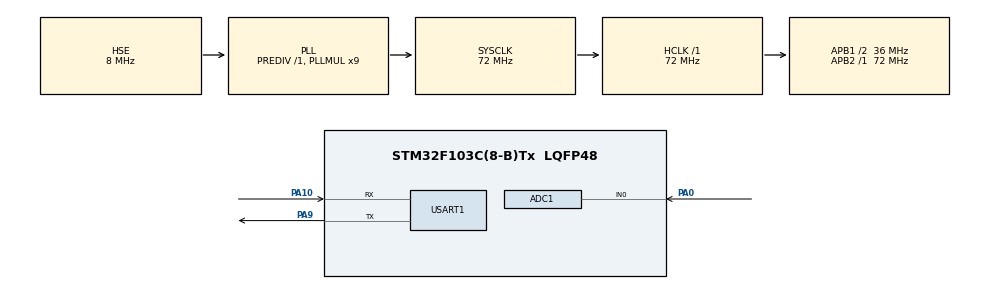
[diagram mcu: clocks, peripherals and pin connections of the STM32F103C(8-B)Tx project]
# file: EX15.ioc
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ADC1.ContinuousConvMode=ENABLE
ADC1.EnableRegularConversion=DISABLE
ADC1.master=1
FREERTOS.Queues01=Queue01,16,uint16_t,0,Dynamic,NULL,NULL
FREERTOS.Tasks01=Task01,0,128,Task01Funct,Default,NULL,Dynamic,NULL,NULL;Task02,0,128,Task02Funct,Default,NULL,Dynamic,NULL,NULL
Mcu.Family=STM32F1
Mcu.Name=STM32F103C(8-B)Tx
Mcu.Package=LQFP48
NVIC.PriorityGroup=NVIC_PRIORITYGROUP_4
NVIC.TIM1_UP_IRQn=true\:15\:0\:false\:false\:true\:false\:false\:true\:true
NVIC.TimeBase=TIM1_UP_IRQn
NVIC.TimeBaseIP=TIM1
PA0-WKUP.Signal=ADCx_IN0
PA10.Mode=Asynchronous
PA10.Signal=USART1_RX
PA13.Mode=Serial_Wire
PA13.Signal=SYS_JTMS-SWDIO
PA14.Mode=Serial_Wire
PA14.Signal=SYS_JTCK-SWCLK
PA9.Mode=Asynchronous
PA9.Signal=USART1_TX
PD0-OSC_IN.Mode=HSE-External-Oscillator
PD0-OSC_IN.Signal=RCC_OSC_IN
PD1-OSC_OUT.Mode=HSE-External-Oscillator
PD1-OSC_OUT.Signal=RCC_OSC_OUT
ProjectManager.HeapSize=0x200
ProjectManager.StackSize=0x400
ProjectManager.TargetToolchain=MDK-ARM V5.32
RCC.ADCPresc=RCC_ADCPCLK2_DIV6
RCC.AHBFreq_Value=72000000
RCC.APB1CLKDivider=RCC_HCLK_DIV2
RCC.APB1Freq_Value=36000000
RCC.APB1TimFreq_Value=72000000
RCC.APB2Freq_Value=72000000
RCC.APB2TimFreq_Value=72000000
RCC.HCLKFreq_Value=72000000
RCC.PLLMUL=RCC_PLL_MUL9
RCC.PLLSourceVirtual=RCC_PLLSOURCE_HSE
RCC.SYSCLKFreq_VALUE=72000000
RCC.SYSCLKSource=RCC_SYSCLKSOURCE_PLLCLK
RCC.USBFreq_Value=72000000
SH.ADCx_IN0.0=ADC1_IN0,IN0
USART1.VirtualMode=VM_ASYNC
VP_FREERTOS_VS_CMSIS_V1.Mode=CMSIS_V1
VP_SYS_VS_tim1.Mode=TIM1
board=custom

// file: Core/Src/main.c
/* USER CODE BEGIN Header */
/**
  ******************************************************************************
  * @file           : main.c
  * @brief          : Main program body
  ******************************************************************************
  * @attention
  *
  * Copyright (c) 2025 STMicroelectronics.
  * All rights reserved.
  *
  * This software is licensed under terms that can be found in the LICENSE file
  * in the root directory of this software component.
  * If no LICENSE file comes with this software, it is provided AS-IS.
  *
  ******************************************************************************
  */
/* USER CODE END Header */
#include "main.h"
#include "cmsis_os.h"

/* USER CODE BEGIN Includes */
#include "string.h"
#include "stdio.h"
/* USER CODE END Includes */

ADC_HandleTypeDef hadc1;

UART_HandleTypeDef huart1;

osThreadId Task01Handle;
osThreadId Task02Handle;
osMessageQId Queue01Handle;

void SystemClock_Config(void);
static void MX_GPIO_Init(void);
static void MX_ADC1_Init(void);
static void MX_USART1_UART_Init(void);
void Task01Funct(void const * argument);
void Task02Funct(void const * argument);

/* USER CODE BEGIN 0 */
void UART1_SendChar(char c){
	HAL_UART_Transmit(&huart1, (uint8_t*)&c, 1, 10);
}

struct __FILE {
    int dummy;
};
FILE __stdout;
int fputc(int ch, FILE *f){
	UART1_SendChar(ch);
	return ch;
}

uint16_t Read_ADC_Value(void){
	uint16_t value = 0;

	HAL_ADC_PollForConversion(&hadc1, 100);
	value = HAL_ADC_GetValue(&hadc1);
	return value;
}

/* USER CODE END 0 */

int main(void)
{

  /* MCU Configuration--------------------------------------------------------*/

  /* Reset of all peripherals, Initializes the Flash interface and the Systick. */
  HAL_Init();

  /* Configure the system clock */
  SystemClock_Config();

  /* Initialize all configured peripherals */
  MX_GPIO_Init();
  MX_ADC1_Init();
  MX_USART1_UART_Init();

  /* Create the queue(s) */
  /* definition and creation of Queue01 */
  osMessageQDef(Queue01, 16, uint16_t);
  Queue01Handle = osMessageCreate(osMessageQ(Queue01), NULL);

  /* Create the thread(s) */
  /* definition and creation of Task01 */
  osThreadDef(Task01, Task01Funct, osPriorityNormal, 0, 128);
  Task01Handle = osThreadCreate(osThread(Task01), NULL);

  /* definition and creation of Task02 */
  osThreadDef(Task02, Task02Funct, osPriorityNormal, 0, 128);
  Task02Handle = osThreadCreate(osThread(Task02), NULL);

  /* Start scheduler */
  osKernelStart();

  /* We should never get here as control is now taken by the scheduler */

  /* Infinite loop */
  while (1)
  {

  }
}

void SystemClock_Config(void)
{
  RCC_OscInitTypeDef RCC_OscInitStruct = {0};
  RCC_ClkInitTypeDef RCC_ClkInitStruct = {0};
  RCC_PeriphCLKInitTypeDef PeriphClkInit = {0};

  /** Initializes the RCC Oscillators according to the specified parameters
  * in the RCC_OscInitTypeDef structure.
  */
  RCC_OscInitStruct.OscillatorType = RCC_OSCILLATORTYPE_HSE;
  RCC_OscInitStruct.HSEState = RCC_HSE_ON;
  RCC_OscInitStruct.HSEPredivValue = RCC_HSE_PREDIV_DIV1;
  RCC_OscInitStruct.HSIState = RCC_HSI_ON;
  RCC_OscInitStruct.PLL.PLLState = RCC_PLL_ON;
  RCC_OscInitStruct.PLL.PLLSource = RCC_PLLSOURCE_HSE;
  RCC_OscInitStruct.PLL.PLLMUL = RCC_PLL_MUL9;
  if (HAL_RCC_OscConfig(&RCC_OscInitStruct) != HAL_OK)
  {
    Error_Handler();
  }

  /** Initializes the CPU, AHB and APB buses clocks
  */
  RCC_ClkInitStruct.ClockType = RCC_CLOCKTYPE_HCLK|RCC_CLOCKTYPE_SYSCLK
                              |RCC_CLOCKTYPE_PCLK1|RCC_CLOCKTYPE_PCLK2;
  RCC_ClkInitStruct.SYSCLKSource = RCC_SYSCLKSOURCE_PLLCLK;
  RCC_ClkInitStruct.AHBCLKDivider = RCC_SYSCLK_DIV1;
  RCC_ClkInitStruct.APB1CLKDivider = RCC_HCLK_DIV2;
  RCC_ClkInitStruct.APB2CLKDivider = RCC_HCLK_DIV1;

  if (HAL_RCC_ClockConfig(&RCC_ClkInitStruct, FLASH_LATENCY_2) != HAL_OK)
  {
    Error_Handler();
  }
  PeriphClkInit.PeriphClockSelection = RCC_PERIPHCLK_ADC;
  PeriphClkInit.AdcClockSelection = RCC_ADCPCLK2_DIV6;
  if (HAL_RCCEx_PeriphCLKConfig(&PeriphClkInit) != HAL_OK)
  {
    Error_Handler();
  }
}

static void MX_ADC1_Init(void)
{

  /** Common config
  */
  hadc1.Instance = ADC1;
  hadc1.Init.ScanConvMode = ADC_SCAN_DISABLE;
  hadc1.Init.ContinuousConvMode = ENABLE;
  hadc1.Init.DiscontinuousConvMode = DISABLE;
  hadc1.Init.ExternalTrigConv = ADC_SOFTWARE_START;
  hadc1.Init.DataAlign = ADC_DATAALIGN_RIGHT;
  hadc1.Init.NbrOfConversion = 1;
  if (HAL_ADC_Init(&hadc1) != HAL_OK)
  {
    Error_Handler();
  }
  /* USER CODE BEGIN ADC1_Init 2 */
	ADC_ChannelConfTypeDef sConfig = {0};
	sConfig.Channel = ADC_CHANNEL_0;              // PA0
	sConfig.Rank = ADC_REGULAR_RANK_1;
	sConfig.SamplingTime = ADC_SAMPLETIME_55CYCLES_5;
	HAL_ADC_ConfigChannel(&hadc1, &sConfig);

  /* USER CODE END ADC1_Init 2 */

}

static void MX_USART1_UART_Init(void)
{

  huart1.Instance = USART1;
  huart1.Init.BaudRate = 115200;
  huart1.Init.WordLength = UART_WORDLENGTH_8B;
  huart1.Init.StopBits = UART_STOPBITS_1;
  huart1.Init.Parity = UART_PARITY_NONE;
  huart1.Init.Mode = UART_MODE_TX_RX;
  huart1.Init.HwFlowCtl = UART_HWCONTROL_NONE;
  huart1.Init.OverSampling = UART_OVERSAMPLING_16;
  if (HAL_UART_Init(&huart1) != HAL_OK)
  {
    Error_Handler();
  }

}

static void MX_GPIO_Init(void)
{

  /* GPIO Ports Clock Enable */
  __HAL_RCC_GPIOD_CLK_ENABLE();
  __HAL_RCC_GPIOA_CLK_ENABLE();

}

void Task01Funct(void const * argument)
{
  /* USER CODE BEGIN 5 */
  /* Infinite loop */
	uint16_t adc_value;
	HAL_ADC_Start(&hadc1);
  for(;;)
  {
		adc_value = Read_ADC_Value();
		printf("Gia tri truyen: %u\n", adc_value);
		osMessagePut(Queue01Handle, adc_value, osWaitForever);
    osDelay(500);
  }
  /* USER CODE END 5 */
}

void Task02Funct(void const * argument)
{
  /* USER CODE BEGIN Task02Funct */
  /* Infinite loop */

  for(;;)
  {
		osEvent event;
		event = osMessageGet(Queue01Handle, osWaitForever);
		if(event.status == osEventMessage){
			uint16_t recei_value = event.value.v;
			printf("Gia tri nhan: %u\n", recei_value);
		}
    osDelay(500);
  }
  /* USER CODE END Task02Funct */
}

void HAL_TIM_PeriodElapsedCallback(TIM_HandleTypeDef *htim)
{
  if (htim->Instance == TIM1) {
    HAL_IncTick();
  }
}

void Error_Handler(void)
{
  __disable_irq();
  while (1)
  {
  }
}
